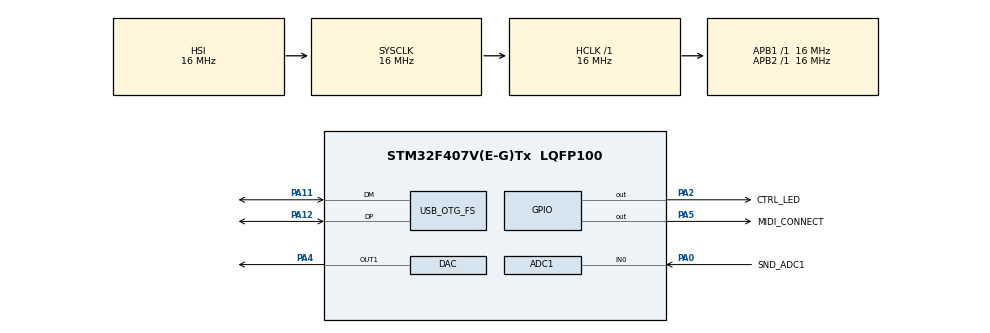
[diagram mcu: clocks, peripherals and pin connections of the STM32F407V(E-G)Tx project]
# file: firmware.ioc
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ADC1.Channel-0\#ChannelRegularConversion=ADC_CHANNEL_0
ADC1.NbrOfConversionFlag=1
ADC1.Rank-0\#ChannelRegularConversion=1
ADC1.SamplingTime-0\#ChannelRegularConversion=ADC_SAMPLETIME_3CYCLES
ADC1.master=1
ARM.CMSIS.5.6.0.CMSISJjCORE=true
ARM.CMSIS.5.6.0.CMSISJjDSP=Library
ARM.CMSIS.5.6.0.CMSISOoDriverJjUSBOoDeviceJjCustom=true
ARM.CMSIS.5.6.0.DeviceJjStartup=COoStartup
DAC.DAC_Trigger=DAC_TRIGGER_NONE
Mcu.Family=STM32F4
Mcu.Name=STM32F407V(E-G)Tx
Mcu.Package=LQFP100
NVIC.OTG_FS_IRQn=true\:0\:0\:false\:false\:true\:false\:true
NVIC.PriorityGroup=NVIC_PRIORITYGROUP_4
NVIC.TIM1_UP_TIM10_IRQn=true\:0\:0\:false\:false\:true\:true\:true
NVIC.TIM2_IRQn=true\:0\:0\:false\:false\:true\:true\:true
NVIC.TIM3_IRQn=true\:0\:0\:false\:false\:true\:true\:true
NVIC.TIM4_IRQn=true\:0\:0\:false\:false\:true\:true\:true
NVIC.TIM6_DAC_IRQn=true\:1\:0\:true\:false\:true\:true\:true
PA0-WKUP.GPIO_Label=SND_ADC1
PA0-WKUP.Signal=ADCx_IN0
PA11.Mode=Device_Only
PA11.Signal=USB_OTG_FS_DM
PA12.Mode=Device_Only
PA12.Signal=USB_OTG_FS_DP
PA13.Mode=Serial_Wire
PA13.Signal=SYS_JTMS-SWDIO
PA14.Mode=Serial_Wire
PA14.Signal=SYS_JTCK-SWCLK
PA2.GPIO_Label=CTRL_LED
PA2.GPIO_PuPd=GPIO_PULLUP
PA2.Signal=GPIO_Output
PA4.Signal=COMP_DAC1_group
PA5.GPIO_Label=MIDI_CONNECT
PA5.GPIO_PuPd=GPIO_PULLUP
PA5.Signal=GPIO_Output
PC14-OSC32_IN.Mode=LSE-External-Oscillator
PC14-OSC32_IN.Signal=RCC_OSC32_IN
PC15-OSC32_OUT.Mode=LSE-External-Oscillator
PC15-OSC32_OUT.Signal=RCC_OSC32_OUT
PH0-OSC_IN.Mode=HSE-External-Oscillator
PH0-OSC_IN.Signal=RCC_OSC_IN
PH1-OSC_OUT.Mode=HSE-External-Oscillator
PH1-OSC_OUT.Signal=RCC_OSC_OUT
ProjectManager.HeapSize=0x200
ProjectManager.StackSize=0x400
ProjectManager.TargetToolchain=SW4STM32
RCC.48MHZClocksFreq_Value=48000000
RCC.AHBFreq_Value=16000000
RCC.APB1Freq_Value=16000000
RCC.APB1TimFreq_Value=16000000
RCC.APB2Freq_Value=16000000
RCC.APB2TimCLKDivider=1
RCC.APB2TimFreq_Value=16000000
RCC.CortexFreq_Value=16000000
RCC.HCLKFreq_Value=16000000
RCC.HSE_VALUE=8000000
RCC.HSICalibrationValue=16
RCC.HSI_VALUE=16000000
RCC.PLLM=4
RCC.PLLN=72
RCC.PLLQ=3
RCC.SYSCLKFreq_VALUE=16000000
RCC.VCOOutputFreq_Value=144000000
SH.ADCx_IN0.0=ADC1_IN0,IN0
SH.COMP_DAC1_group.0=DAC_OUT1,DAC_OUT1
TIM2.Period=16666
TIM3.Period=10000
TIM3.Prescaler=399
TIM4.Period=10000
TIM4.Prescaler=3999
TIM6.Period=15
TIM6.Prescaler=0
TIM6.TIM_MasterOutputTrigger=TIM_TRGO_RESET
USB_DEVICE.CLASS_NAME_FS=CDC
USB_DEVICE.CONFIGURATION_STRING_CDC_FS=MIDI Config
USB_DEVICE.INTERFACE_STRING_CDC_FS=MIDI Interface
USB_DEVICE.MANUFACTURER_STRING-CDC_FS=elektrophon
USB_DEVICE.PRODUCT_STRING_CDC_FS=klang
USB_DEVICE.VirtualMode-CDC_FS=Cdc
USB_DEVICE.VirtualModeFS=Cdc_FS
USB_OTG_FS.VirtualMode=Device_Only
VP_ARM.CMSIS_VS_CMSISJjCORE_5.3.0.Mode=CMSISJjCORE
VP_ARM.CMSIS_VS_CMSISJjDSP_1.7.0.Mode=CMSISJjDSP
VP_TIM1_VS_ClockSourceINT.Mode=Internal
VP_TIM2_VS_ClockSourceINT.Mode=Internal
VP_TIM3_VS_ClockSourceINT.Mode=Internal
VP_TIM4_VS_ClockSourceINT.Mode=Internal
VP_TIM6_VS_ClockSourceINT.Mode=Enable_Timer
VP_USB_DEVICE_VS_USB_DEVICE_CDC_FS.Mode=CDC_FS
board=custom

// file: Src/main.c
/* USER CODE BEGIN Header */
/**
  ******************************************************************************
  * @file           : main.c
  * @brief          : Main program body
  ******************************************************************************
  * @attention
  *
  * <h2><center>&copy; Copyright (c) 2020 STMicroelectronics.
  * All rights reserved.</center></h2>
  *
  * This software component is licensed by ST under Ultimate Liberty license
  * SLA0044, the "License"; You may not use this file except in compliance with
  * the License. You may obtain a copy of the License at:
  *                             www.st.com/SLA0044
  *
  ******************************************************************************
  */
/* USER CODE END Header */

#include "main.h"
#include "usb_device.h"

/* USER CODE BEGIN Includes */
#include "usbd_midi_if.h"
#include "oszillator.h"
/* USER CODE END Includes */

ADC_HandleTypeDef hadc1;

DAC_HandleTypeDef hdac;

TIM_HandleTypeDef htim1;
TIM_HandleTypeDef htim2;
TIM_HandleTypeDef htim3;
TIM_HandleTypeDef htim4;
TIM_HandleTypeDef htim6;

void SystemClock_Config(void);
static void MX_GPIO_Init(void);
static void MX_ADC1_Init(void);
static void MX_DAC_Init(void);
static void MX_TIM1_Init(void);
static void MX_TIM2_Init(void);
static void MX_TIM6_Init(void);
static void MX_TIM3_Init(void);
static void MX_TIM4_Init(void);

int main(void)
{
  /* USER CODE BEGIN 1 */
	oszillator_init();
	mimuz_init();
	setHdlNoteOn(note_on);
	setHdlNoteOff(note_off);
  /* USER CODE END 1 */

  /* MCU Configuration--------------------------------------------------------*/

  /* Reset of all peripherals, Initializes the Flash interface and the Systick. */
  HAL_Init();

  /* Configure the system clock */
  SystemClock_Config();

  /* Initialize all configured peripherals */
  MX_GPIO_Init();
  MX_ADC1_Init();
  MX_DAC_Init();
  MX_USB_DEVICE_Init();
  MX_TIM1_Init();
  MX_TIM2_Init();
  MX_TIM6_Init();
  MX_TIM3_Init();
  MX_TIM4_Init();
  /* USER CODE BEGIN 2 */

	HAL_DAC_SetValue(&hdac, DAC_CHANNEL_1, DAC_ALIGN_12B_R, 2048);
	if (HAL_DAC_Start(&hdac, DAC_CHANNEL_1) != HAL_OK)
	{
	  /* Start Error */
	  Error_Handler();
	}
//	HAL_DAC_Start_DMA(&hdac, DAC_CHANNEL_1, (uint32_t*)wt_sine, 1024, DAC_ALIGN_12B_R);

	HAL_TIM_Base_Start_IT(&htim2);
	HAL_TIM_Base_Start_IT(&htim3);
	HAL_TIM_Base_Start_IT(&htim4);
	HAL_TIM_Base_Start_IT(&htim6);
	//TODO    HAL_ADC_Start(&hadc1);
  /* USER CODE END 2 */

  /* Infinite loop */
  /* USER CODE BEGIN WHILE */
  while (1)
  {
//		while (1)
//		{
//			if(USBD_STATE_CONFIGURED == hUsbDeviceFS.dev_state)
//			{
//				//TODO				HAL_TIM_Base_Start_IT(&htim6);
//				HAL_GPIO_WritePin(MIDI_CONNECT_GPIO_Port, MIDI_CONNECT_Pin, SET);
//				break;
//			} else
//			{
////TODO				HAL_TIM_Base_Stop_IT(&htim6);
//				HAL_GPIO_WritePin(MIDI_CONNECT_GPIO_Port, MIDI_CONNECT_Pin, SET);
//				HAL_Delay(200);
//				HAL_GPIO_WritePin(MIDI_CONNECT_GPIO_Port, MIDI_CONNECT_Pin, RESET);
//				HAL_Delay(200);
//			}
//		}
    /* USER CODE END WHILE */

    /* USER CODE BEGIN 3 */
//	processMidiMessage();
//	HAL_Delay(10);
  }
  /* USER CODE END 3 */
}

void SystemClock_Config(void)
{
  RCC_OscInitTypeDef RCC_OscInitStruct = {0};
  RCC_ClkInitTypeDef RCC_ClkInitStruct = {0};

  /** Configure the main internal regulator output voltage
  */
  __HAL_RCC_PWR_CLK_ENABLE();
  __HAL_PWR_VOLTAGESCALING_CONFIG(PWR_REGULATOR_VOLTAGE_SCALE1);
  /** Initializes the CPU, AHB and APB busses clocks
  */
  RCC_OscInitStruct.OscillatorType = RCC_OSCILLATORTYPE_HSI|RCC_OSCILLATORTYPE_HSE;
  RCC_OscInitStruct.HSEState = RCC_HSE_ON;
  RCC_OscInitStruct.HSIState = RCC_HSI_ON;
  RCC_OscInitStruct.HSICalibrationValue = RCC_HSICALIBRATION_DEFAULT;
  RCC_OscInitStruct.PLL.PLLState = RCC_PLL_ON;
  RCC_OscInitStruct.PLL.PLLSource = RCC_PLLSOURCE_HSE;
  RCC_OscInitStruct.PLL.PLLM = 4;
  RCC_OscInitStruct.PLL.PLLN = 72;
  RCC_OscInitStruct.PLL.PLLP = RCC_PLLP_DIV2;
  RCC_OscInitStruct.PLL.PLLQ = 3;
  if (HAL_RCC_OscConfig(&RCC_OscInitStruct) != HAL_OK)
  {
    Error_Handler();
  }
  /** Initializes the CPU, AHB and APB busses clocks
  */
  RCC_ClkInitStruct.ClockType = RCC_CLOCKTYPE_HCLK|RCC_CLOCKTYPE_SYSCLK
                              |RCC_CLOCKTYPE_PCLK1|RCC_CLOCKTYPE_PCLK2;
  RCC_ClkInitStruct.SYSCLKSource = RCC_SYSCLKSOURCE_HSI;
  RCC_ClkInitStruct.AHBCLKDivider = RCC_SYSCLK_DIV1;
  RCC_ClkInitStruct.APB1CLKDivider = RCC_HCLK_DIV1;
  RCC_ClkInitStruct.APB2CLKDivider = RCC_HCLK_DIV1;

  if (HAL_RCC_ClockConfig(&RCC_ClkInitStruct, FLASH_LATENCY_0) != HAL_OK)
  {
    Error_Handler();
  }
}

static void MX_ADC1_Init(void)
{

  ADC_ChannelConfTypeDef sConfig = {0};

  /** Configure the global features of the ADC (Clock, Resolution, Data Alignment and number of conversion)
  */
  hadc1.Instance = ADC1;
  hadc1.Init.ClockPrescaler = ADC_CLOCK_SYNC_PCLK_DIV2;
  hadc1.Init.Resolution = ADC_RESOLUTION_12B;
  hadc1.Init.ScanConvMode = DISABLE;
  hadc1.Init.ContinuousConvMode = DISABLE;
  hadc1.Init.DiscontinuousConvMode = DISABLE;
  hadc1.Init.ExternalTrigConvEdge = ADC_EXTERNALTRIGCONVEDGE_NONE;
  hadc1.Init.ExternalTrigConv = ADC_SOFTWARE_START;
  hadc1.Init.DataAlign = ADC_DATAALIGN_RIGHT;
  hadc1.Init.NbrOfConversion = 1;
  hadc1.Init.DMAContinuousRequests = DISABLE;
  hadc1.Init.EOCSelection = ADC_EOC_SINGLE_CONV;
  if (HAL_ADC_Init(&hadc1) != HAL_OK)
  {
    Error_Handler();
  }
  /** Configure for the selected ADC regular channel its corresponding rank in the sequencer and its sample time.
  */
  sConfig.Channel = ADC_CHANNEL_0;
  sConfig.Rank = 1;
  sConfig.SamplingTime = ADC_SAMPLETIME_3CYCLES;
  if (HAL_ADC_ConfigChannel(&hadc1, &sConfig) != HAL_OK)
  {
    Error_Handler();
  }

}

static void MX_DAC_Init(void)
{

  DAC_ChannelConfTypeDef sConfig = {0};

  /** DAC Initialization
  */
  hdac.Instance = DAC;
  if (HAL_DAC_Init(&hdac) != HAL_OK)
  {
    Error_Handler();
  }
  /** DAC channel OUT1 config
  */
  sConfig.DAC_Trigger = DAC_TRIGGER_NONE;
  sConfig.DAC_OutputBuffer = DAC_OUTPUTBUFFER_ENABLE;
  if (HAL_DAC_ConfigChannel(&hdac, &sConfig, DAC_CHANNEL_1) != HAL_OK)
  {
    Error_Handler();
  }

}

static void MX_TIM1_Init(void)
{

  TIM_ClockConfigTypeDef sClockSourceConfig = {0};
  TIM_MasterConfigTypeDef sMasterConfig = {0};

  htim1.Instance = TIM1;
  htim1.Init.Prescaler = 0;
  htim1.Init.CounterMode = TIM_COUNTERMODE_UP;
  htim1.Init.Period = 0;
  htim1.Init.ClockDivision = TIM_CLOCKDIVISION_DIV1;
  htim1.Init.RepetitionCounter = 0;
  htim1.Init.AutoReloadPreload = TIM_AUTORELOAD_PRELOAD_DISABLE;
  if (HAL_TIM_Base_Init(&htim1) != HAL_OK)
  {
    Error_Handler();
  }
  sClockSourceConfig.ClockSource = TIM_CLOCKSOURCE_INTERNAL;
  if (HAL_TIM_ConfigClockSource(&htim1, &sClockSourceConfig) != HAL_OK)
  {
    Error_Handler();
  }
  sMasterConfig.MasterOutputTrigger = TIM_TRGO_RESET;
  sMasterConfig.MasterSlaveMode = TIM_MASTERSLAVEMODE_DISABLE;
  if (HAL_TIMEx_MasterConfigSynchronization(&htim1, &sMasterConfig) != HAL_OK)
  {
    Error_Handler();
  }

}

static void MX_TIM2_Init(void)
{

  TIM_ClockConfigTypeDef sClockSourceConfig = {0};
  TIM_MasterConfigTypeDef sMasterConfig = {0};

  htim2.Instance = TIM2;
  htim2.Init.Prescaler = 0;
  htim2.Init.CounterMode = TIM_COUNTERMODE_UP;
  htim2.Init.Period = 999;
  htim2.Init.ClockDivision = TIM_CLOCKDIVISION_DIV1;
  htim2.Init.AutoReloadPreload = TIM_AUTORELOAD_PRELOAD_DISABLE;
  if (HAL_TIM_Base_Init(&htim2) != HAL_OK)
  {
    Error_Handler();
  }
  sClockSourceConfig.ClockSource = TIM_CLOCKSOURCE_INTERNAL;
  if (HAL_TIM_ConfigClockSource(&htim2, &sClockSourceConfig) != HAL_OK)
  {
    Error_Handler();
  }
  sMasterConfig.MasterOutputTrigger = TIM_TRGO_RESET;
  sMasterConfig.MasterSlaveMode = TIM_MASTERSLAVEMODE_DISABLE;
  if (HAL_TIMEx_MasterConfigSynchronization(&htim2, &sMasterConfig) != HAL_OK)
  {
    Error_Handler();
  }

}

static void MX_TIM3_Init(void)
{

  TIM_ClockConfigTypeDef sClockSourceConfig = {0};
  TIM_MasterConfigTypeDef sMasterConfig = {0};

  htim3.Instance = TIM3;
  htim3.Init.Prescaler = 399;
  htim3.Init.CounterMode = TIM_COUNTERMODE_UP;
  htim3.Init.Period = 10000;
  htim3.Init.ClockDivision = TIM_CLOCKDIVISION_DIV1;
  htim3.Init.AutoReloadPreload = TIM_AUTORELOAD_PRELOAD_DISABLE;
  if (HAL_TIM_Base_Init(&htim3) != HAL_OK)
  {
    Error_Handler();
  }
  sClockSourceConfig.ClockSource = TIM_CLOCKSOURCE_INTERNAL;
  if (HAL_TIM_ConfigClockSource(&htim3, &sClockSourceConfig) != HAL_OK)
  {
    Error_Handler();
  }
  sMasterConfig.MasterOutputTrigger = TIM_TRGO_RESET;
  sMasterConfig.MasterSlaveMode = TIM_MASTERSLAVEMODE_DISABLE;
  if (HAL_TIMEx_MasterConfigSynchronization(&htim3, &sMasterConfig) != HAL_OK)
  {
    Error_Handler();
  }

}

static void MX_TIM4_Init(void)
{

  TIM_ClockConfigTypeDef sClockSourceConfig = {0};
  TIM_MasterConfigTypeDef sMasterConfig = {0};

  htim4.Instance = TIM4;
  htim4.Init.Prescaler = 3999;
  htim4.Init.CounterMode = TIM_COUNTERMODE_UP;
  htim4.Init.Period = 10000;
  htim4.Init.ClockDivision = TIM_CLOCKDIVISION_DIV1;
  htim4.Init.AutoReloadPreload = TIM_AUTORELOAD_PRELOAD_DISABLE;
  if (HAL_TIM_Base_Init(&htim4) != HAL_OK)
  {
    Error_Handler();
  }
  sClockSourceConfig.ClockSource = TIM_CLOCKSOURCE_INTERNAL;
  if (HAL_TIM_ConfigClockSource(&htim4, &sClockSourceConfig) != HAL_OK)
  {
    Error_Handler();
  }
  sMasterConfig.MasterOutputTrigger = TIM_TRGO_RESET;
  sMasterConfig.MasterSlaveMode = TIM_MASTERSLAVEMODE_DISABLE;
  if (HAL_TIMEx_MasterConfigSynchronization(&htim4, &sMasterConfig) != HAL_OK)
  {
    Error_Handler();
  }

}

static void MX_TIM6_Init(void)
{

  TIM_MasterConfigTypeDef sMasterConfig = {0};

  htim6.Instance = TIM6;
  htim6.Init.Prescaler = 0;
  htim6.Init.CounterMode = TIM_COUNTERMODE_UP;
  htim6.Init.Period = 29;
  htim6.Init.AutoReloadPreload = TIM_AUTORELOAD_PRELOAD_DISABLE;
  if (HAL_TIM_Base_Init(&htim6) != HAL_OK)
  {
    Error_Handler();
  }
  sMasterConfig.MasterOutputTrigger = TIM_TRGO_RESET;
  sMasterConfig.MasterSlaveMode = TIM_MASTERSLAVEMODE_DISABLE;
  if (HAL_TIMEx_MasterConfigSynchronization(&htim6, &sMasterConfig) != HAL_OK)
  {
    Error_Handler();
  }

}

static void MX_GPIO_Init(void)
{
  GPIO_InitTypeDef GPIO_InitStruct = {0};

  /* GPIO Ports Clock Enable */
  __HAL_RCC_GPIOC_CLK_ENABLE();
  __HAL_RCC_GPIOH_CLK_ENABLE();
  __HAL_RCC_GPIOA_CLK_ENABLE();

  /*Configure GPIO pin Output Level */
  HAL_GPIO_WritePin(GPIOA, CTRL_LED_Pin|MIDI_CONNECT_Pin, GPIO_PIN_RESET);

  /*Configure GPIO pins : CTRL_LED_Pin MIDI_CONNECT_Pin */
  GPIO_InitStruct.Pin = CTRL_LED_Pin|MIDI_CONNECT_Pin;
  GPIO_InitStruct.Mode = GPIO_MODE_OUTPUT_PP;
  GPIO_InitStruct.Pull = GPIO_PULLUP;
  GPIO_InitStruct.Speed = GPIO_SPEED_FREQ_LOW;
  HAL_GPIO_Init(GPIOA, &GPIO_InitStruct);

}

void Error_Handler(void)
{
}

/************************ (C) COPYRIGHT STMicroelectronics *****END OF FILE****/
